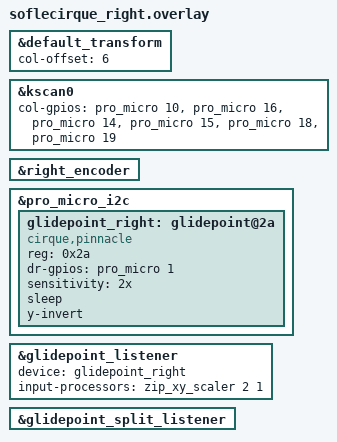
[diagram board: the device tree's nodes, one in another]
/*
 * Copyright (c) 2020 Ryan Cross
 *
 * SPDX-License-Identifier: MIT
 */

#include "soflecirque.dtsi"
#include <input/processors.dtsi>

&default_transform {
    col-offset = <6>;
};

&kscan0 {
    col-gpios
        = <&pro_micro 10 GPIO_ACTIVE_HIGH>
        , <&pro_micro 16 GPIO_ACTIVE_HIGH>
        , <&pro_micro 14 GPIO_ACTIVE_HIGH>
        , <&pro_micro 15 GPIO_ACTIVE_HIGH>
        , <&pro_micro 18 GPIO_ACTIVE_HIGH>
        , <&pro_micro 19 GPIO_ACTIVE_HIGH>
        ;
};

&right_encoder {
    status = "okay";
};

&pro_micro_i2c {
    status = "okay";

    glidepoint_right: glidepoint@2a {
        compatible = "cirque,pinnacle";
        reg = <0x2a>;
        status = "okay";
        dr-gpios = <&pro_micro 1 (GPIO_ACTIVE_HIGH)>;
        // ATENUACION del ADC, no ganancia: "1x" | "2x" | "3x" | "4x"
        // Numero MAS BAJO = menos atenuacion = MAS sensible (overlay grueso)
        // Numero MAS ALTO = mas atenuacion = MENOS sensible (overlay fino)
        // "3x" dejo el trackpad sin detectar toques. "2x" es el valor que funciona.
        sensitivity = "2x";
        sleep;
        //no-taps;
        y-invert;
        //x-invert;
    };
};

&glidepoint_listener {
    status = "okay";
    device = <&glidepoint_right>;
    // Velocidad del cursor = multiplicador / divisor.
    // <2 1> = doble de rapido | <3 2> = 1.5x | <1 1> = original | <3 1> = triple
    input-processors = <&zip_xy_scaler 2 1>;
};

&glidepoint_split_listener {
    status = "okay";
};
